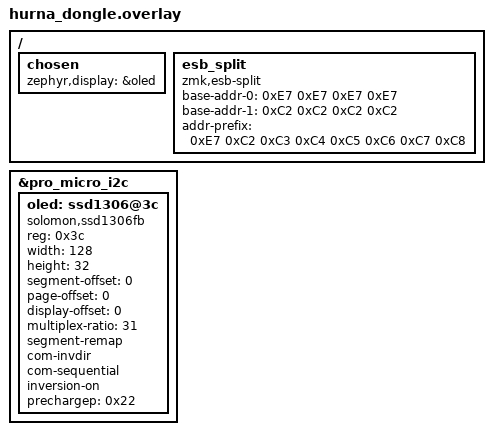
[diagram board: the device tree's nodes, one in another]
#include "hurna.dtsi"
#include "hurna_left.overlay"

/ {
    chosen {
        zephyr,display = &oled;
    };
};

&pro_micro_i2c {
    status = "okay";

    oled: ssd1306@3c {
        compatible = "solomon,ssd1306fb";
        reg = <0x3c>;
        width = <128>;
        height = <32>;
        segment-offset = <0>;
        page-offset = <0>;
        display-offset = <0>;
        multiplex-ratio = <31>;
        segment-remap;
        com-invdir;
        com-sequential;
        inversion-on;
        prechargep = <0x22>;
    };
}; 

/{
    esb_split {
        compatible = "zmk,esb-split";
        base-addr-0 = <0xE7 0xE7 0xE7 0xE7>;
        base-addr-1 = <0xC2 0xC2 0xC2 0xC2>;
        addr-prefix = <0xE7 0xC2 0xC3 0xC4 0xC5 0xC6 0xC7 0xC8>;
    };
};
